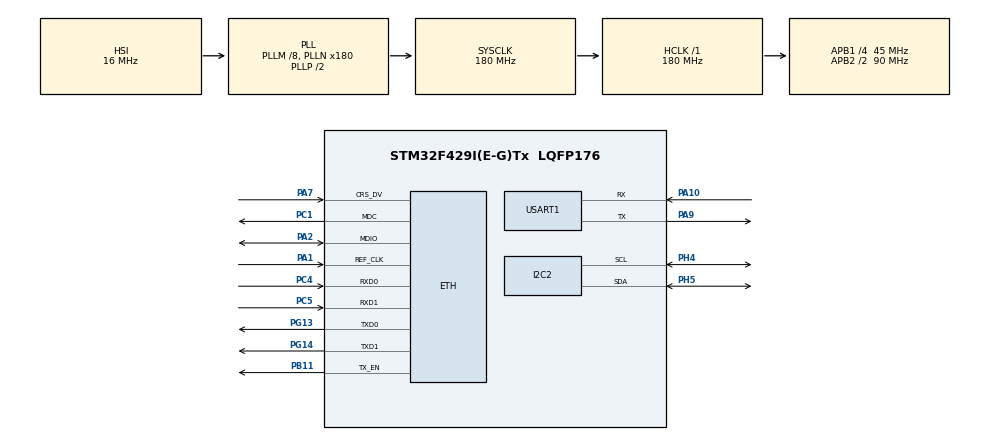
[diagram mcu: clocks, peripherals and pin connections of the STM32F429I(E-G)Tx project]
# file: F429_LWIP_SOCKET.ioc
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ETH.MediaInterface=HAL_ETH_RMII_MODE
FREERTOS.Tasks01=defaultTask,24,1024,StartDefaultTask,Default,NULL,Dynamic,NULL,NULL
FREERTOS.configUSE_NEWLIB_REENTRANT=1
LWIP.BSP.number=1
LWIP.GATEWAY_ADDRESS=172.016.020.001
LWIP.IP_ADDRESS=172.016.020.039
LWIP.LWIP_DHCP=0
LWIP.NETMASK_ADDRESS=255.255.255.000
LWIP.Version=v2.1.2_Cube
LWIP0.BSP.STBoard=false
LWIP0.BSP.api=BSP_COMPONENT_DRIVER
LWIP0.BSP.component=LAN8742
LWIP0.BSP.instance=LAN8742
LWIP0.BSP.name=Driver_PHY
LWIP0.BSP.semaphore=S_LAN8742
LWIP0.BSP.solution=LAN8742
Mcu.Family=STM32F4
Mcu.Name=STM32F429I(E-G)Tx
Mcu.Package=LQFP176
NVIC.ETH_IRQn=true\:5\:0\:false\:false\:true\:true\:false\:true\:true
NVIC.PriorityGroup=NVIC_PRIORITYGROUP_4
NVIC.TIM1_UP_TIM10_IRQn=true\:15\:0\:false\:false\:true\:false\:false\:true\:true
NVIC.TimeBase=TIM1_UP_TIM10_IRQn
NVIC.TimeBaseIP=TIM1
PA1.Mode=RMII
PA1.Signal=ETH_REF_CLK
PA10.Mode=Asynchronous
PA10.Signal=USART1_RX
PA13.Mode=Serial_Wire
PA13.Signal=SYS_JTMS-SWDIO
PA14.Mode=Serial_Wire
PA14.Signal=SYS_JTCK-SWCLK
PA2.Mode=RMII
PA2.Signal=ETH_MDIO
PA7.Mode=RMII
PA7.Signal=ETH_CRS_DV
PA9.Mode=Asynchronous
PA9.Signal=USART1_TX
PB11.Mode=RMII
PB11.Signal=ETH_TX_EN
PC1.Mode=RMII
PC1.Signal=ETH_MDC
PC14/OSC32_IN.Mode=LSE-External-Oscillator
PC14/OSC32_IN.Signal=RCC_OSC32_IN
PC15/OSC32_OUT.Mode=LSE-External-Oscillator
PC15/OSC32_OUT.Signal=RCC_OSC32_OUT
PC4.Mode=RMII
PC4.Signal=ETH_RXD0
PC5.Mode=RMII
PC5.Signal=ETH_RXD1
PG13.Mode=RMII
PG13.Signal=ETH_TXD0
PG14.Mode=RMII
PG14.Signal=ETH_TXD1
PH0/OSC_IN.Mode=HSE-External-Oscillator
PH0/OSC_IN.Signal=RCC_OSC_IN
PH1/OSC_OUT.Mode=HSE-External-Oscillator
PH1/OSC_OUT.Signal=RCC_OSC_OUT
PH4.Mode=I2C
PH4.Signal=I2C2_SCL
PH5.Mode=I2C
PH5.Signal=I2C2_SDA
ProjectManager.HeapSize=0x200
ProjectManager.StackSize=0x400
ProjectManager.TargetToolchain=STM32CubeIDE
RCC.48MHZClocksFreq_Value=90000000
RCC.AHBFreq_Value=180000000
RCC.APB1CLKDivider=RCC_HCLK_DIV4
RCC.APB1Freq_Value=45000000
RCC.APB1TimFreq_Value=90000000
RCC.APB2CLKDivider=RCC_HCLK_DIV2
RCC.APB2Freq_Value=90000000
RCC.APB2TimFreq_Value=180000000
RCC.CortexFreq_Value=180000000
RCC.HCLKFreq_Value=180000000
RCC.HSE_VALUE=25000000
RCC.HSI_VALUE=16000000
RCC.PLLM=8
RCC.PLLN=180
RCC.SYSCLKFreq_VALUE=180000000
RCC.SYSCLKSource=RCC_SYSCLKSOURCE_PLLCLK
RCC.VCOOutputFreq_Value=360000000
USART1.VirtualMode=VM_ASYNC
VP_FREERTOS_VS_CMSIS_V2.Mode=CMSIS_V2
VP_LWIP_VS_Enabled.Mode=Enabled
VP_SYS_VS_tim1.Mode=TIM1
board=custom

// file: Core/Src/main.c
/* USER CODE BEGIN Header */
/**
  ******************************************************************************
  * @file           : main.c
  * @brief          : Main program body
  ******************************************************************************
  * @attention
  *
  * Copyright (c) 2024 STMicroelectronics.
  * All rights reserved.
  *
  * This software is licensed under terms that can be found in the LICENSE file
  * in the root directory of this software component.
  * If no LICENSE file comes with this software, it is provided AS-IS.
  *
  ******************************************************************************
  */
/* USER CODE END Header */
#include "main.h"
#include "cmsis_os.h"
#include "lwip.h"

/* USER CODE BEGIN Includes */
#include <stdio.h>
#include "client_socket.h"
#include "server_socket.h"
/* USER CODE END Includes */

I2C_HandleTypeDef hi2c2;

UART_HandleTypeDef huart1;

/* Definitions for defaultTask */
osThreadId_t defaultTaskHandle;
const osThreadAttr_t defaultTask_attributes = {
  .name = "defaultTask",
  .stack_size = 1024 * 4,
  .priority = (osPriority_t) osPriorityNormal,
};

void SystemClock_Config(void);
static void MX_GPIO_Init(void);
static void MX_USART1_UART_Init(void);
static void MX_I2C2_Init(void);
void StartDefaultTask(void *argument);

/* USER CODE BEGIN 0 */

#ifdef __GNUC__ // 串口重定向
#define PUTCHAR_PROTOTYPE int __io_putchar(int ch)
#else
#define PUTCHAR_PROTOTYPE int fputc(int ch, FILE *f)
#endif
PUTCHAR_PROTOTYPE
{
  HAL_UART_Transmit(&huart1, (uint8_t *)&ch, 1, 0xFFFF);
  return ch;
}

/* USER CODE END 0 */

int main(void)
{

  /* MCU Configuration--------------------------------------------------------*/

  /* Reset of all peripherals, Initializes the Flash interface and the Systick. */
  HAL_Init();

  /* Configure the system clock */
  SystemClock_Config();

  /* Initialize all configured peripherals */
  MX_GPIO_Init();
  MX_USART1_UART_Init();
  MX_I2C2_Init();

  /* Init scheduler */
  osKernelInitialize();

  /* Create the thread(s) */
  /* creation of defaultTask */
  defaultTaskHandle = osThreadNew(StartDefaultTask, NULL, &defaultTask_attributes);

  /* Start scheduler */
  osKernelStart();

  /* We should never get here as control is now taken by the scheduler */

  /* Infinite loop */
  while (1)
  {

  }
}

void SystemClock_Config(void)
{
  RCC_OscInitTypeDef RCC_OscInitStruct = {0};
  RCC_ClkInitTypeDef RCC_ClkInitStruct = {0};

  /** Configure the main internal regulator output voltage
  */
  __HAL_RCC_PWR_CLK_ENABLE();
  __HAL_PWR_VOLTAGESCALING_CONFIG(PWR_REGULATOR_VOLTAGE_SCALE1);

  /** Initializes the RCC Oscillators according to the specified parameters
  * in the RCC_OscInitTypeDef structure.
  */
  RCC_OscInitStruct.OscillatorType = RCC_OSCILLATORTYPE_HSI;
  RCC_OscInitStruct.HSIState = RCC_HSI_ON;
  RCC_OscInitStruct.HSICalibrationValue = RCC_HSICALIBRATION_DEFAULT;
  RCC_OscInitStruct.PLL.PLLState = RCC_PLL_ON;
  RCC_OscInitStruct.PLL.PLLSource = RCC_PLLSOURCE_HSI;
  RCC_OscInitStruct.PLL.PLLM = 8;
  RCC_OscInitStruct.PLL.PLLN = 180;
  RCC_OscInitStruct.PLL.PLLP = RCC_PLLP_DIV2;
  RCC_OscInitStruct.PLL.PLLQ = 4;
  if (HAL_RCC_OscConfig(&RCC_OscInitStruct) != HAL_OK)
  {
    Error_Handler();
  }

  /** Activate the Over-Drive mode
  */
  if (HAL_PWREx_EnableOverDrive() != HAL_OK)
  {
    Error_Handler();
  }

  /** Initializes the CPU, AHB and APB buses clocks
  */
  RCC_ClkInitStruct.ClockType = RCC_CLOCKTYPE_HCLK|RCC_CLOCKTYPE_SYSCLK
                              |RCC_CLOCKTYPE_PCLK1|RCC_CLOCKTYPE_PCLK2;
  RCC_ClkInitStruct.SYSCLKSource = RCC_SYSCLKSOURCE_PLLCLK;
  RCC_ClkInitStruct.AHBCLKDivider = RCC_SYSCLK_DIV1;
  RCC_ClkInitStruct.APB1CLKDivider = RCC_HCLK_DIV4;
  RCC_ClkInitStruct.APB2CLKDivider = RCC_HCLK_DIV2;

  if (HAL_RCC_ClockConfig(&RCC_ClkInitStruct, FLASH_LATENCY_5) != HAL_OK)
  {
    Error_Handler();
  }
}

static void MX_I2C2_Init(void)
{

  hi2c2.Instance = I2C2;
  hi2c2.Init.ClockSpeed = 100000;
  hi2c2.Init.DutyCycle = I2C_DUTYCYCLE_2;
  hi2c2.Init.OwnAddress1 = 0;
  hi2c2.Init.AddressingMode = I2C_ADDRESSINGMODE_7BIT;
  hi2c2.Init.DualAddressMode = I2C_DUALADDRESS_DISABLE;
  hi2c2.Init.OwnAddress2 = 0;
  hi2c2.Init.GeneralCallMode = I2C_GENERALCALL_DISABLE;
  hi2c2.Init.NoStretchMode = I2C_NOSTRETCH_DISABLE;
  if (HAL_I2C_Init(&hi2c2) != HAL_OK)
  {
    Error_Handler();
  }

  /** Configure Analogue filter
  */
  if (HAL_I2CEx_ConfigAnalogFilter(&hi2c2, I2C_ANALOGFILTER_ENABLE) != HAL_OK)
  {
    Error_Handler();
  }

  /** Configure Digital filter
  */
  if (HAL_I2CEx_ConfigDigitalFilter(&hi2c2, 0) != HAL_OK)
  {
    Error_Handler();
  }

}

static void MX_USART1_UART_Init(void)
{

  huart1.Instance = USART1;
  huart1.Init.BaudRate = 115200;
  huart1.Init.WordLength = UART_WORDLENGTH_8B;
  huart1.Init.StopBits = UART_STOPBITS_1;
  huart1.Init.Parity = UART_PARITY_NONE;
  huart1.Init.Mode = UART_MODE_TX_RX;
  huart1.Init.HwFlowCtl = UART_HWCONTROL_NONE;
  huart1.Init.OverSampling = UART_OVERSAMPLING_16;
  if (HAL_UART_Init(&huart1) != HAL_OK)
  {
    Error_Handler();
  }

}

static void MX_GPIO_Init(void)
{

  /* GPIO Ports Clock Enable */
  __HAL_RCC_GPIOC_CLK_ENABLE();
  __HAL_RCC_GPIOH_CLK_ENABLE();
  __HAL_RCC_GPIOA_CLK_ENABLE();
  __HAL_RCC_GPIOB_CLK_ENABLE();
  __HAL_RCC_GPIOG_CLK_ENABLE();

}

void StartDefaultTask(void *argument)
{
  /* init code for LWIP */
  MX_LWIP_Init();
  /* USER CODE BEGIN 5 */
  printf("init\r\n");
//  client_socket_init();
  server_socket_init();
  printf("success\r\n");
  /* Infinite loop */
  for(;;)
  {
    osDelay(1);
  }
  /* USER CODE END 5 */
}

void HAL_TIM_PeriodElapsedCallback(TIM_HandleTypeDef *htim)
{
  if (htim->Instance == TIM1) {
    HAL_IncTick();
  }
}

void Error_Handler(void)
{
  __disable_irq();
  while (1)
  {
  }
}
